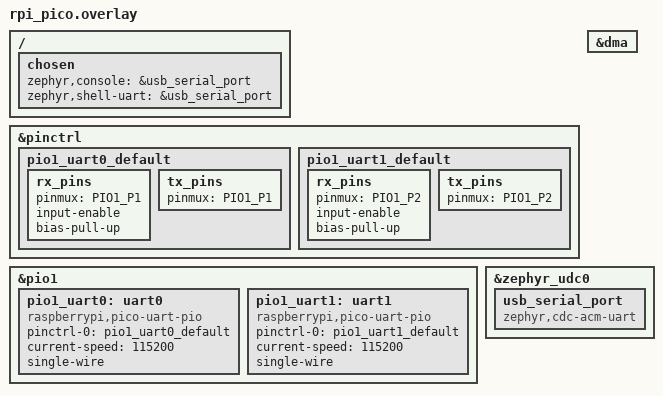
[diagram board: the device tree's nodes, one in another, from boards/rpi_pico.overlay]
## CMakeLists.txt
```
# SPDX-License-Identifier: Apache-2.0

cmake_minimum_required(VERSION 3.28.0)
find_package(Zephyr REQUIRED HINTS $ENV{ZEPHYR_BASE})
project(uart_pio_single_wire)

target_sources(app PRIVATE
    src/main.c
    )
```

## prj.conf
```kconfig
# SPDX-FileCopyrightText: Copyright The Zephyr Project Contributors
# SPDX-License-Identifier: Apache-2.0

# Nothing needed here
CONFIG_LOG=y
CONFIG_LOG_MODE_DEFERRED=y
CONFIG_LOG_RUNTIME_FILTERING=y
CONFIG_LOG_BUFFER_SIZE=2048
CONFIG_LOG_PRINTK=y
CONFIG_LOG_PROCESS_TRIGGER_THRESHOLD=0
CONFIG_COVERAGE=n
CONFIG_LOG_TAG_MAX_LEN=8

CONFIG_STDOUT_CONSOLE=y
CONFIG_USB_DEVICE_STACK=y
CONFIG_USB_DEVICE_PRODUCT="Raspberry Pi Pico Example for Zephyr"
CONFIG_USB_DEVICE_VID=0x2E8A
CONFIG_USB_DEVICE_PID=0x0001

CONFIG_USB_DEVICE_INITIALIZE_AT_BOOT=y

CONFIG_SERIAL=y
CONFIG_UART_LINE_CTRL=y

CONFIG_USB_DRIVER_LOG_LEVEL_ERR=y
CONFIG_USB_DEVICE_LOG_LEVEL_ERR=y
CONFIG_USB_CDC_ACM_LOG_LEVEL_ERR=y
CONFIG_BOOT_DELAY=4000
```

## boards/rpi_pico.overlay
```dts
&pinctrl {
	pio1_uart0_default: pio1_uart0_default {
		rx_pins {
			pinmux = <PIO1_P1>;
			input-enable;
			bias-pull-up;
		};

		tx_pins {
			pinmux = <PIO1_P1>;
		};
	};

	pio1_uart1_default: pio1_uart1_default {
		rx_pins {
			pinmux = <PIO1_P2>;
			input-enable;
			bias-pull-up;
		};

		tx_pins {
			pinmux = <PIO1_P2>;
		};
	};


};

&dma {
	status = "okay";
};

&pio1 {
	status = "okay";

	pio1_uart0: uart0 {
		pinctrl-0 = <&pio1_uart0_default>;
		pinctrl-names = "default";

		compatible = "raspberrypi,pico-uart-pio";
		current-speed = <115200>;
		single-wire;
		status = "okay";
	};

	pio1_uart1: uart1 {
		pinctrl-0 = <&pio1_uart1_default>;
		pinctrl-names = "default";

		compatible = "raspberrypi,pico-uart-pio";
		current-speed = <115200>;
		single-wire;
		status = "okay";
	};
};
&zephyr_udc0 {
	usb_serial_port: usb_serial_port {
		compatible = "zephyr,cdc-acm-uart";
	};
};
/ {
	chosen {
		zephyr,console = &usb_serial_port;
		zephyr,shell-uart = &usb_serial_port;
	};
};
```

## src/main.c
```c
/*
 * Copyright (c) 2021 Jonathan Hahn
 *
 * SPDX-License-Identifier: Apache-2.0
 */

#include <zephyr/kernel.h>
#include <zephyr/device.h>
#include <zephyr/drivers/uart.h>

int main(void)
{
	const struct device *uart0 = DEVICE_DT_GET(DT_NODELABEL(pio1_uart0));
	const struct device *uart1 = DEVICE_DT_GET(DT_NODELABEL(pio1_uart1));


	unsigned char recv;

	if (!device_is_ready(uart0) || !device_is_ready(uart1)) {
		printk("uart devices not ready\n");
		return 0;
	}

	while (true) {

		uart_poll_out(uart0, 'c');

		/* give the uarts some time to get the data through */
		k_sleep(K_MSEC(50));

		int ret = uart_poll_in(uart1, &recv);

		if (ret < 0) {
			printk("Receiving failed. Error: %d\n", ret);
		} else {
			printk("Received %c\n", recv);
		}

		k_sleep(K_MSEC(2000));
	}
	return 0;
}
```
